# MIMXRT1052 register map
Vendor: nxp.com; File version: 1.0
CPU: CM7 r0p1, little endian, MPU, FPU, VTOR, 4 interrupt priority bits
Registers are 32-bit, read-write, reset 0x0 unless marked. A register's access mark holds for its fields unless they carry their own. Offsets are from the block's base; [hi:lo] are bit positions; {n}, {i} and the like mark numbered series; 'fields as' and 'values as' point back to an identical list.

## IOMUXC (part 3 of 4)
Base 0x401F8000; register names take the prefix IOMUXC_
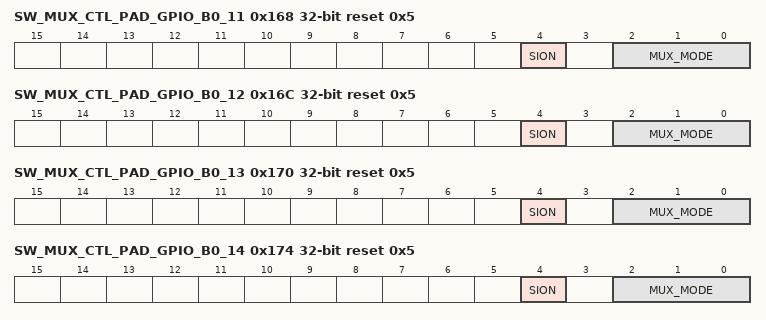
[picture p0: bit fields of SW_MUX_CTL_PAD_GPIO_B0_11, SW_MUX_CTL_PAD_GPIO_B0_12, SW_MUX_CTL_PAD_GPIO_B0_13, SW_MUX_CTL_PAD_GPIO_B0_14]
0x168 SW_MUX_CTL_PAD_GPIO_B0_11 reset 0x5 — SW_MUX_CTL_PAD_GPIO_B0_11 SW MUX Control Register
  [4] SION — Software Input On Field.
    0=DISABLED (Input Path is determined by functionality); 1=ENABLED (Force input path of pad GPIO_B0_11)
  [2:0] MUX_MODE — MUX Mode Select Field. Note: Some functions are available on multiple pins. A given function should not be selected for more than one pin.
    0=ALT0 (Select mux mode: ALT0 mux port: LCD_DATA07 of instance: lcdif); 1=ALT1 (Select mux mode: ALT1 mux port: TMR4_TIMER2 of instance: qtimer4); 2=ALT2 (Select mux mode: ALT2 mux port: FLEXPWM2_PWM2_B of instance: flexpwm2); 3=ALT3 (Select mux mode: ALT3 mux port: SAI1_TX_DATA02 of instance: sai1); 4=ALT4 (Select mux mode: ALT4 mux port: FLEXIO2_D11 of instance: flexio2); 5=ALT5 (Select mux mode: ALT5 mux port: GPIO2_IO11 of instance: gpio2); 6=ALT6 (Select mux mode: ALT6 mux port: SRC_BT_CFG07 of instance: src)
0x16C SW_MUX_CTL_PAD_GPIO_B0_12 reset 0x5 — SW_MUX_CTL_PAD_GPIO_B0_12 SW MUX Control Register
  [4] SION — Software Input On Field.
    0=DISABLED (Input Path is determined by functionality); 1=ENABLED (Force input path of pad GPIO_B0_12)
  [2:0] MUX_MODE — MUX Mode Select Field. Note: Some functions are available on multiple pins. A given function should not be selected for more than one pin.
    0=ALT0 (Select mux mode: ALT0 mux port: LCD_DATA08 of instance: lcdif); 1=ALT1 (Select mux mode: ALT1 mux port: XBAR1_INOUT10 of instance: xbar1); 2=ALT2 (Select mux mode: ALT2 mux port: ARM_TRACE_CLK of instance: cm7_mx6rt); 3=ALT3 (Select mux mode: ALT3 mux port: SAI1_TX_DATA01 of instance: sai1); 4=ALT4 (Select mux mode: ALT4 mux port: FLEXIO2_D12 of instance: flexio2); 5=ALT5 (Select mux mode: ALT5 mux port: GPIO2_IO12 of instance: gpio2); 6=ALT6 (Select mux mode: ALT6 mux port: SRC_BT_CFG08 of instance: src)
0x170 SW_MUX_CTL_PAD_GPIO_B0_13 reset 0x5 — SW_MUX_CTL_PAD_GPIO_B0_13 SW MUX Control Register
  [4] SION — Software Input On Field.
    0=DISABLED (Input Path is determined by functionality); 1=ENABLED (Force input path of pad GPIO_B0_13)
  [2:0] MUX_MODE — MUX Mode Select Field. Note: Some functions are available on multiple pins. A given function should not be selected for more than one pin.
    0=ALT0 (Select mux mode: ALT0 mux port: LCD_DATA09 of instance: lcdif); 1=ALT1 (Select mux mode: ALT1 mux port: XBAR1_INOUT11 of instance: xbar1); 2=ALT2 (Select mux mode: ALT2 mux port: ARM_TRACE_SWO of instance: cm7_mx6rt); 3=ALT3 (Select mux mode: ALT3 mux port: SAI1_MCLK of instance: sai1); 4=ALT4 (Select mux mode: ALT4 mux port: FLEXIO2_D13 of instance: flexio2); 5=ALT5 (Select mux mode: ALT5 mux port: GPIO2_IO13 of instance: gpio2); 6=ALT6 (Select mux mode: ALT6 mux port: SRC_BT_CFG09 of instance: src)
0x174 SW_MUX_CTL_PAD_GPIO_B0_14 reset 0x5 — SW_MUX_CTL_PAD_GPIO_B0_14 SW MUX Control Register
  [4] SION — Software Input On Field.
    0=DISABLED (Input Path is determined by functionality); 1=ENABLED (Force input path of pad GPIO_B0_14)
  [2:0] MUX_MODE — MUX Mode Select Field. Note: Some functions are available on multiple pins. A given function should not be selected for more than one pin.
    0=ALT0 (Select mux mode: ALT0 mux port: LCD_DATA10 of instance: lcdif); 1=ALT1 (Select mux mode: ALT1 mux port: XBAR1_INOUT12 of instance: xbar1); 2=ALT2 (Select mux mode: ALT2 mux port: ARM_CM7_TXEV of instance: cm7_mx6rt); 3=ALT3 (Select mux mode: ALT3 mux port: SAI1_RX_SYNC of instance: sai1); 4=ALT4 (Select mux mode: ALT4 mux port: FLEXIO2_D14 of instance: flexio2); 5=ALT5 (Select mux mode: ALT5 mux port: GPIO2_IO14 of instance: gpio2); 6=ALT6 (Select mux mode: ALT6 mux port: SRC_BT_CFG10 of instance: src)
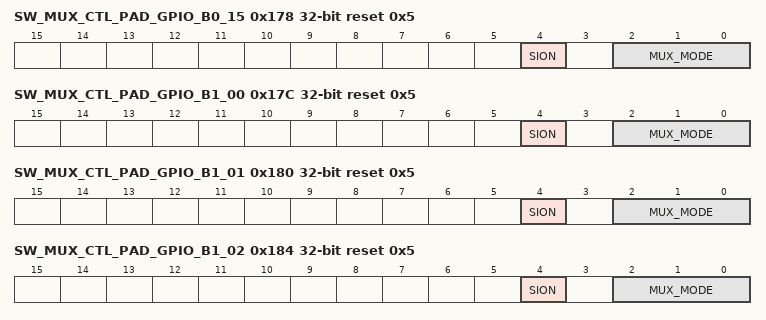
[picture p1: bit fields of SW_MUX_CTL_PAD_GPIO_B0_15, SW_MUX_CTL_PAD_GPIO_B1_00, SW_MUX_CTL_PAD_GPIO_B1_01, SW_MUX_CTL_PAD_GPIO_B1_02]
0x178 SW_MUX_CTL_PAD_GPIO_B0_15 reset 0x5 — SW_MUX_CTL_PAD_GPIO_B0_15 SW MUX Control Register
  [4] SION — Software Input On Field.
    0=DISABLED (Input Path is determined by functionality); 1=ENABLED (Force input path of pad GPIO_B0_15)
  [2:0] MUX_MODE — MUX Mode Select Field. Note: Some functions are available on multiple pins. A given function should not be selected for more than one pin.
    0=ALT0 (Select mux mode: ALT0 mux port: LCD_DATA11 of instance: lcdif); 1=ALT1 (Select mux mode: ALT1 mux port: XBAR1_INOUT13 of instance: xbar1); 2=ALT2 (Select mux mode: ALT2 mux port: ARM_CM7_RXEV of instance: cm7_mx6rt); 3=ALT3 (Select mux mode: ALT3 mux port: SAI1_RX_BCLK of instance: sai1); 4=ALT4 (Select mux mode: ALT4 mux port: FLEXIO2_D15 of instance: flexio2); 5=ALT5 (Select mux mode: ALT5 mux port: GPIO2_IO15 of instance: gpio2); 6=ALT6 (Select mux mode: ALT6 mux port: SRC_BT_CFG11 of instance: src)
0x17C SW_MUX_CTL_PAD_GPIO_B1_00 reset 0x5 — SW_MUX_CTL_PAD_GPIO_B1_00 SW MUX Control Register
  [4] SION — Software Input On Field.
    0=DISABLED (Input Path is determined by functionality); 1=ENABLED (Force input path of pad GPIO_B1_00)
  [2:0] MUX_MODE — MUX Mode Select Field. Note: Some functions are available on multiple pins. A given function should not be selected for more than one pin.
    0=ALT0 (Select mux mode: ALT0 mux port: LCD_DATA12 of instance: lcdif); 1=ALT1 (Select mux mode: ALT1 mux port: XBAR1_INOUT14 of instance: xbar1); 2=ALT2 (Select mux mode: ALT2 mux port: LPUART4_TXD of instance: lpuart4); 3=ALT3 (Select mux mode: ALT3 mux port: SAI1_RX_DATA00 of instance: sai1); 4=ALT4 (Select mux mode: ALT4 mux port: FLEXIO2_D16 of instance: flexio2); 5=ALT5 (Select mux mode: ALT5 mux port: GPIO2_IO16 of instance: gpio2); 6=ALT6 (Select mux mode: ALT6 mux port: FLEXPWM1_PWM3_A of instance: flexpwm1)
0x180 SW_MUX_CTL_PAD_GPIO_B1_01 reset 0x5 — SW_MUX_CTL_PAD_GPIO_B1_01 SW MUX Control Register
  [4] SION — Software Input On Field.
    0=DISABLED (Input Path is determined by functionality); 1=ENABLED (Force input path of pad GPIO_B1_01)
  [2:0] MUX_MODE — MUX Mode Select Field. Note: Some functions are available on multiple pins. A given function should not be selected for more than one pin.
    0=ALT0 (Select mux mode: ALT0 mux port: LCD_DATA13 of instance: lcdif); 1=ALT1 (Select mux mode: ALT1 mux port: XBAR1_INOUT15 of instance: xbar1); 2=ALT2 (Select mux mode: ALT2 mux port: LPUART4_RXD of instance: lpuart4); 3=ALT3 (Select mux mode: ALT3 mux port: SAI1_TX_DATA00 of instance: sai1); 4=ALT4 (Select mux mode: ALT4 mux port: FLEXIO2_D17 of instance: flexio2); 5=ALT5 (Select mux mode: ALT5 mux port: GPIO2_IO17 of instance: gpio2); 6=ALT6 (Select mux mode: ALT6 mux port: FLEXPWM1_PWM3_B of instance: flexpwm1)
0x184 SW_MUX_CTL_PAD_GPIO_B1_02 reset 0x5 — SW_MUX_CTL_PAD_GPIO_B1_02 SW MUX Control Register
  [4] SION — Software Input On Field.
    0=DISABLED (Input Path is determined by functionality); 1=ENABLED (Force input path of pad GPIO_B1_02)
  [2:0] MUX_MODE — MUX Mode Select Field. Note: Some functions are available on multiple pins. A given function should not be selected for more than one pin.
    0=ALT0 (Select mux mode: ALT0 mux port: LCD_DATA14 of instance: lcdif); 1=ALT1 (Select mux mode: ALT1 mux port: XBAR1_INOUT16 of instance: xbar1); 2=ALT2 (Select mux mode: ALT2 mux port: LPSPI4_PCS2 of instance: lpspi4); 3=ALT3 (Select mux mode: ALT3 mux port: SAI1_TX_BCLK of instance: sai1); 4=ALT4 (Select mux mode: ALT4 mux port: FLEXIO2_D18 of instance: flexio2); 5=ALT5 (Select mux mode: ALT5 mux port: GPIO2_IO18 of instance: gpio2); 6=ALT6 (Select mux mode: ALT6 mux port: FLEXPWM2_PWM3_A of instance: flexpwm2)
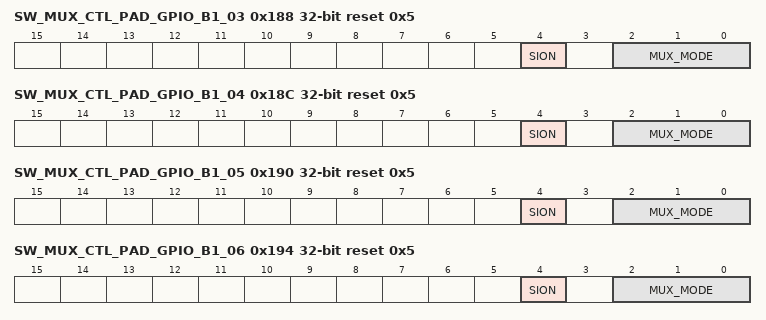
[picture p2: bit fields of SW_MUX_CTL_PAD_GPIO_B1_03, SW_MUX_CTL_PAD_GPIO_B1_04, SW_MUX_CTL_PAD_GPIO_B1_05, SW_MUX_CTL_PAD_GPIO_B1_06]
0x188 SW_MUX_CTL_PAD_GPIO_B1_03 reset 0x5 — SW_MUX_CTL_PAD_GPIO_B1_03 SW MUX Control Register
  [4] SION — Software Input On Field.
    0=DISABLED (Input Path is determined by functionality); 1=ENABLED (Force input path of pad GPIO_B1_03)
  [2:0] MUX_MODE — MUX Mode Select Field. Note: Some functions are available on multiple pins. A given function should not be selected for more than one pin.
    0=ALT0 (Select mux mode: ALT0 mux port: LCD_DATA15 of instance: lcdif); 1=ALT1 (Select mux mode: ALT1 mux port: XBAR1_INOUT17 of instance: xbar1); 2=ALT2 (Select mux mode: ALT2 mux port: LPSPI4_PCS1 of instance: lpspi4); 3=ALT3 (Select mux mode: ALT3 mux port: SAI1_TX_SYNC of instance: sai1); 4=ALT4 (Select mux mode: ALT4 mux port: FLEXIO2_D19 of instance: flexio2); 5=ALT5 (Select mux mode: ALT5 mux port: GPIO2_IO19 of instance: gpio2); 6=ALT6 (Select mux mode: ALT6 mux port: FLEXPWM2_PWM3_B of instance: flexpwm2)
0x18C SW_MUX_CTL_PAD_GPIO_B1_04 reset 0x5 — SW_MUX_CTL_PAD_GPIO_B1_04 SW MUX Control Register
  [4] SION — Software Input On Field.
    0=DISABLED (Input Path is determined by functionality); 1=ENABLED (Force input path of pad GPIO_B1_04)
  [2:0] MUX_MODE — MUX Mode Select Field. Note: Some functions are available on multiple pins. A given function should not be selected for more than one pin.
    0=ALT0 (Select mux mode: ALT0 mux port: LCD_DATA16 of instance: lcdif); 1=ALT1 (Select mux mode: ALT1 mux port: LPSPI4_PCS0 of instance: lpspi4); 2=ALT2 (Select mux mode: ALT2 mux port: CSI_DATA15 of instance: csi); 3=ALT3 (Select mux mode: ALT3 mux port: ENET_RX_DATA00 of instance: enet); 4=ALT4 (Select mux mode: ALT4 mux port: FLEXIO2_D20 of instance: flexio2); 5=ALT5 (Select mux mode: ALT5 mux port: GPIO2_IO20 of instance: gpio2)
0x190 SW_MUX_CTL_PAD_GPIO_B1_05 reset 0x5 — SW_MUX_CTL_PAD_GPIO_B1_05 SW MUX Control Register
  [4] SION — Software Input On Field.
    0=DISABLED (Input Path is determined by functionality); 1=ENABLED (Force input path of pad GPIO_B1_05)
  [2:0] MUX_MODE — MUX Mode Select Field. Note: Some functions are available on multiple pins. A given function should not be selected for more than one pin.
    0=ALT0 (Select mux mode: ALT0 mux port: LCD_DATA17 of instance: lcdif); 1=ALT1 (Select mux mode: ALT1 mux port: LPSPI4_SDI of instance: lpspi4); 2=ALT2 (Select mux mode: ALT2 mux port: CSI_DATA14 of instance: csi); 3=ALT3 (Select mux mode: ALT3 mux port: ENET_RX_DATA01 of instance: enet); 4=ALT4 (Select mux mode: ALT4 mux port: FLEXIO2_D21 of instance: flexio2); 5=ALT5 (Select mux mode: ALT5 mux port: GPIO2_IO21 of instance: gpio2)
0x194 SW_MUX_CTL_PAD_GPIO_B1_06 reset 0x5 — SW_MUX_CTL_PAD_GPIO_B1_06 SW MUX Control Register
  [4] SION — Software Input On Field.
    0=DISABLED (Input Path is determined by functionality); 1=ENABLED (Force input path of pad GPIO_B1_06)
  [2:0] MUX_MODE — MUX Mode Select Field. Note: Some functions are available on multiple pins. A given function should not be selected for more than one pin.
    0=ALT0 (Select mux mode: ALT0 mux port: LCD_DATA18 of instance: lcdif); 1=ALT1 (Select mux mode: ALT1 mux port: LPSPI4_SDO of instance: lpspi4); 2=ALT2 (Select mux mode: ALT2 mux port: CSI_DATA13 of instance: csi); 3=ALT3 (Select mux mode: ALT3 mux port: ENET_RX_EN of instance: enet); 4=ALT4 (Select mux mode: ALT4 mux port: FLEXIO2_D22 of instance: flexio2); 5=ALT5 (Select mux mode: ALT5 mux port: GPIO2_IO22 of instance: gpio2)
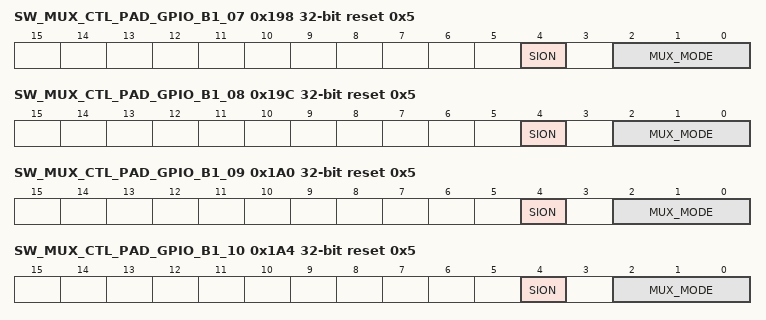
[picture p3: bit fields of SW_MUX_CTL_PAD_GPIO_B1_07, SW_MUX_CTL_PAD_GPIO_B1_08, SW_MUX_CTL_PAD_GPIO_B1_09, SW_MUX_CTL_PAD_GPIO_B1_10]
0x198 SW_MUX_CTL_PAD_GPIO_B1_07 reset 0x5 — SW_MUX_CTL_PAD_GPIO_B1_07 SW MUX Control Register
  [4] SION — Software Input On Field.
    0=DISABLED (Input Path is determined by functionality); 1=ENABLED (Force input path of pad GPIO_B1_07)
  [2:0] MUX_MODE — MUX Mode Select Field. Note: Some functions are available on multiple pins. A given function should not be selected for more than one pin.
    0=ALT0 (Select mux mode: ALT0 mux port: LCD_DATA19 of instance: lcdif); 1=ALT1 (Select mux mode: ALT1 mux port: LPSPI4_SCK of instance: lpspi4); 2=ALT2 (Select mux mode: ALT2 mux port: CSI_DATA12 of instance: csi); 3=ALT3 (Select mux mode: ALT3 mux port: ENET_TX_DATA00 of instance: enet); 4=ALT4 (Select mux mode: ALT4 mux port: FLEXIO2_D23 of instance: flexio2); 5=ALT5 (Select mux mode: ALT5 mux port: GPIO2_IO23 of instance: gpio2)
0x19C SW_MUX_CTL_PAD_GPIO_B1_08 reset 0x5 — SW_MUX_CTL_PAD_GPIO_B1_08 SW MUX Control Register
  [4] SION — Software Input On Field.
    0=DISABLED (Input Path is determined by functionality); 1=ENABLED (Force input path of pad GPIO_B1_08)
  [2:0] MUX_MODE — MUX Mode Select Field. Note: Some functions are available on multiple pins. A given function should not be selected for more than one pin.
    0=ALT0 (Select mux mode: ALT0 mux port: LCD_DATA20 of instance: lcdif); 1=ALT1 (Select mux mode: ALT1 mux port: TMR1_TIMER3 of instance: qtimer1); 2=ALT2 (Select mux mode: ALT2 mux port: CSI_DATA11 of instance: csi); 3=ALT3 (Select mux mode: ALT3 mux port: ENET_TX_DATA01 of instance: enet); 4=ALT4 (Select mux mode: ALT4 mux port: FLEXIO2_D24 of instance: flexio2); 5=ALT5 (Select mux mode: ALT5 mux port: GPIO2_IO24 of instance: gpio2); 6=ALT6 (Select mux mode: ALT6 mux port: FLEXCAN2_TX of instance: flexcan2)
0x1A0 SW_MUX_CTL_PAD_GPIO_B1_09 reset 0x5 — SW_MUX_CTL_PAD_GPIO_B1_09 SW MUX Control Register
  [4] SION — Software Input On Field.
    0=DISABLED (Input Path is determined by functionality); 1=ENABLED (Force input path of pad GPIO_B1_09)
  [2:0] MUX_MODE — MUX Mode Select Field. Note: Some functions are available on multiple pins. A given function should not be selected for more than one pin.
    0=ALT0 (Select mux mode: ALT0 mux port: LCD_DATA21 of instance: lcdif); 1=ALT1 (Select mux mode: ALT1 mux port: TMR2_TIMER3 of instance: qtimer2); 2=ALT2 (Select mux mode: ALT2 mux port: CSI_DATA10 of instance: csi); 3=ALT3 (Select mux mode: ALT3 mux port: ENET_TX_EN of instance: enet); 4=ALT4 (Select mux mode: ALT4 mux port: FLEXIO2_D25 of instance: flexio2); 5=ALT5 (Select mux mode: ALT5 mux port: GPIO2_IO25 of instance: gpio2); 6=ALT6 (Select mux mode: ALT6 mux port: FLEXCAN2_RX of instance: flexcan2)
0x1A4 SW_MUX_CTL_PAD_GPIO_B1_10 reset 0x5 — SW_MUX_CTL_PAD_GPIO_B1_10 SW MUX Control Register
  [4] SION — Software Input On Field.
    0=DISABLED (Input Path is determined by functionality); 1=ENABLED (Force input path of pad GPIO_B1_10)
  [2:0] MUX_MODE — MUX Mode Select Field. Note: Some functions are available on multiple pins. A given function should not be selected for more than one pin.
    0=ALT0 (Select mux mode: ALT0 mux port: LCD_DATA22 of instance: lcdif); 1=ALT1 (Select mux mode: ALT1 mux port: TMR3_TIMER3 of instance: qtimer3); 2=ALT2 (Select mux mode: ALT2 mux port: CSI_DATA00 of instance: csi); 3=ALT3 (Select mux mode: ALT3 mux port: ENET_TX_CLK of instance: enet); 4=ALT4 (Select mux mode: ALT4 mux port: FLEXIO2_D26 of instance: flexio2); 5=ALT5 (Select mux mode: ALT5 mux port: GPIO2_IO26 of instance: gpio2); 6=ALT6 (Select mux mode: ALT6 mux port: ENET_REF_CLK of instance: enet)
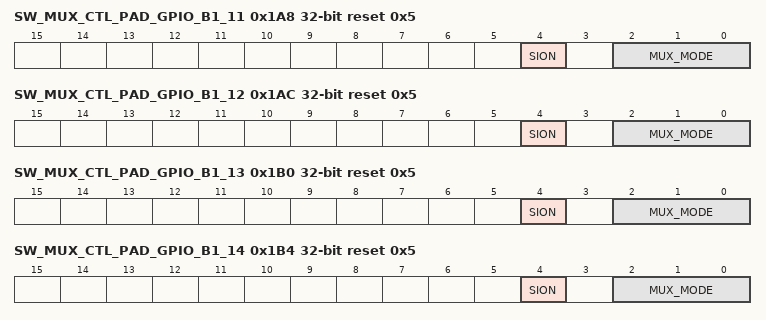
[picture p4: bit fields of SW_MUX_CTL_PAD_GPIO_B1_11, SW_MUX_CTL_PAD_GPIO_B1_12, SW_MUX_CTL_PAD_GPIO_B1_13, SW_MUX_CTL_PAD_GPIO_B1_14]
0x1A8 SW_MUX_CTL_PAD_GPIO_B1_11 reset 0x5 — SW_MUX_CTL_PAD_GPIO_B1_11 SW MUX Control Register
  [4] SION — Software Input On Field.
    0=DISABLED (Input Path is determined by functionality); 1=ENABLED (Force input path of pad GPIO_B1_11)
  [2:0] MUX_MODE — MUX Mode Select Field. Note: Some functions are available on multiple pins. A given function should not be selected for more than one pin.
    0=ALT0 (Select mux mode: ALT0 mux port: LCD_DATA23 of instance: lcdif); 1=ALT1 (Select mux mode: ALT1 mux port: TMR4_TIMER3 of instance: qtimer4); 2=ALT2 (Select mux mode: ALT2 mux port: CSI_DATA01 of instance: csi); 3=ALT3 (Select mux mode: ALT3 mux port: ENET_RX_ER of instance: enet); 4=ALT4 (Select mux mode: ALT4 mux port: FLEXIO2_D27 of instance: flexio2); 5=ALT5 (Select mux mode: ALT5 mux port: GPIO2_IO27 of instance: gpio2); 6=ALT6 (Select mux mode: ALT6 mux port: LPSPI4_PCS3 of instance: lpspi4)
0x1AC SW_MUX_CTL_PAD_GPIO_B1_12 reset 0x5 — SW_MUX_CTL_PAD_GPIO_B1_12 SW MUX Control Register
  [4] SION — Software Input On Field.
    0=DISABLED (Input Path is determined by functionality); 1=ENABLED (Force input path of pad GPIO_B1_12)
  [2:0] MUX_MODE — MUX Mode Select Field. Note: Some functions are available on multiple pins. A given function should not be selected for more than one pin.
    1=ALT1 (Select mux mode: ALT1 mux port: LPUART5_TXD of instance: lpuart5); 2=ALT2 (Select mux mode: ALT2 mux port: CSI_PIXCLK of instance: csi); 3=ALT3 (Select mux mode: ALT3 mux port: ENET_1588_EVENT0_IN of instance: enet); 4=ALT4 (Select mux mode: ALT4 mux port: FLEXIO2_D28 of instance: flexio2); 5=ALT5 (Select mux mode: ALT5 mux port: GPIO2_IO28 of instance: gpio2); 6=ALT6 (Select mux mode: ALT6 mux port: USDHC1_CD_B of instance: usdhc1)
0x1B0 SW_MUX_CTL_PAD_GPIO_B1_13 reset 0x5 — SW_MUX_CTL_PAD_GPIO_B1_13 SW MUX Control Register
  [4] SION — Software Input On Field.
    0=DISABLED (Input Path is determined by functionality); 1=ENABLED (Force input path of pad GPIO_B1_13)
  [2:0] MUX_MODE — MUX Mode Select Field. Note: Some functions are available on multiple pins. A given function should not be selected for more than one pin.
    0=ALT0 (Select mux mode: ALT0 mux port: WDOG1_B of instance: wdog1); 1=ALT1 (Select mux mode: ALT1 mux port: LPUART5_RXD of instance: lpuart5); 2=ALT2 (Select mux mode: ALT2 mux port: CSI_VSYNC of instance: csi); 3=ALT3 (Select mux mode: ALT3 mux port: ENET_1588_EVENT0_OUT of instance: enet); 4=ALT4 (Select mux mode: ALT4 mux port: FLEXIO2_D29 of instance: flexio2); 5=ALT5 (Select mux mode: ALT5 mux port: GPIO2_IO29 of instance: gpio2); 6=ALT6 (Select mux mode: ALT6 mux port: USDHC1_WP of instance: usdhc1)
0x1B4 SW_MUX_CTL_PAD_GPIO_B1_14 reset 0x5 — SW_MUX_CTL_PAD_GPIO_B1_14 SW MUX Control Register
  [4] SION — Software Input On Field.
    0=DISABLED (Input Path is determined by functionality); 1=ENABLED (Force input path of pad GPIO_B1_14)
  [2:0] MUX_MODE — MUX Mode Select Field. Note: Some functions are available on multiple pins. A given function should not be selected for more than one pin.
    0=ALT0 (Select mux mode: ALT0 mux port: ENET_MDC of instance: enet); 1=ALT1 (Select mux mode: ALT1 mux port: FLEXPWM4_PWM2_A of instance: flexpwm4); 2=ALT2 (Select mux mode: ALT2 mux port: CSI_HSYNC of instance: csi); 3=ALT3 (Select mux mode: ALT3 mux port: XBAR1_IN02 of instance: xbar1); 4=ALT4 (Select mux mode: ALT4 mux port: FLEXIO2_D30 of instance: flexio2); 5=ALT5 (Select mux mode: ALT5 mux port: GPIO2_IO30 of instance: gpio2); 6=ALT6 (Select mux mode: ALT6 mux port: USDHC1_VSELECT of instance: usdhc1)
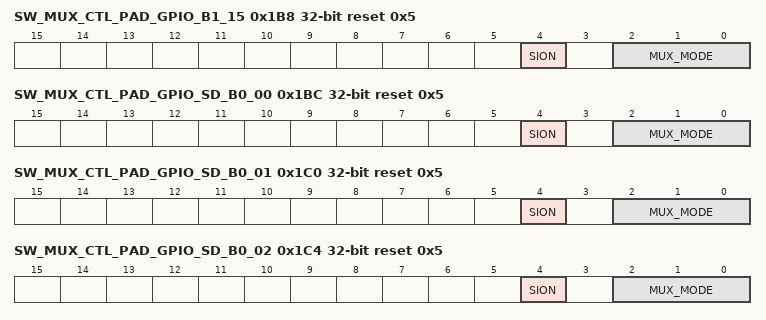
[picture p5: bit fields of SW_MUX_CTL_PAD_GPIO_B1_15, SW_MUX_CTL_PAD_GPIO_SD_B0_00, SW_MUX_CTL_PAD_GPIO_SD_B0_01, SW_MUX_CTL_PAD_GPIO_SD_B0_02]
0x1B8 SW_MUX_CTL_PAD_GPIO_B1_15 reset 0x5 — SW_MUX_CTL_PAD_GPIO_B1_15 SW MUX Control Register
  [4] SION — Software Input On Field.
    0=DISABLED (Input Path is determined by functionality); 1=ENABLED (Force input path of pad GPIO_B1_15)
  [2:0] MUX_MODE — MUX Mode Select Field. Note: Some functions are available on multiple pins. A given function should not be selected for more than one pin.
    0=ALT0 (Select mux mode: ALT0 mux port: ENET_MDIO of instance: enet); 1=ALT1 (Select mux mode: ALT1 mux port: FLEXPWM4_PWM3_A of instance: flexpwm4); 2=ALT2 (Select mux mode: ALT2 mux port: CSI_MCLK of instance: csi); 3=ALT3 (Select mux mode: ALT3 mux port: XBAR1_IN03 of instance: xbar1); 4=ALT4 (Select mux mode: ALT4 mux port: FLEXIO2_D31 of instance: flexio2); 5=ALT5 (Select mux mode: ALT5 mux port: GPIO2_IO31 of instance: gpio2); 6=ALT6 (Select mux mode: ALT6 mux port: USDHC1_RESET_B of instance: usdhc1)
0x1BC SW_MUX_CTL_PAD_GPIO_SD_B0_00 reset 0x5 — SW_MUX_CTL_PAD_GPIO_SD_B0_00 SW MUX Control Register
  [4] SION — Software Input On Field.
    0=DISABLED (Input Path is determined by functionality); 1=ENABLED (Force input path of pad GPIO_SD_B0_00)
  [2:0] MUX_MODE — MUX Mode Select Field. Note: Some functions are available on multiple pins. A given function should not be selected for more than one pin.
    0=ALT0 (Select mux mode: ALT0 mux port: USDHC1_CMD of instance: usdhc1); 1=ALT1 (Select mux mode: ALT1 mux port: FLEXPWM1_PWM0_A of instance: flexpwm1); 2=ALT2 (Select mux mode: ALT2 mux port: LPI2C3_SCL of instance: lpi2c3); 3=ALT3 (Select mux mode: ALT3 mux port: XBAR1_INOUT04 of instance: xbar1); 4=ALT4 (Select mux mode: ALT4 mux port: LPSPI1_SCK of instance: lpspi1); 5=ALT5 (Select mux mode: ALT5 mux port: GPIO3_IO12 of instance: gpio3); 6=ALT6 (Select mux mode: ALT6 mux port: FLEXSPI_A_SS1_B of instance: flexspi)
0x1C0 SW_MUX_CTL_PAD_GPIO_SD_B0_01 reset 0x5 — SW_MUX_CTL_PAD_GPIO_SD_B0_01 SW MUX Control Register
  [4] SION — Software Input On Field.
    0=DISABLED (Input Path is determined by functionality); 1=ENABLED (Force input path of pad GPIO_SD_B0_01)
  [2:0] MUX_MODE — MUX Mode Select Field. Note: Some functions are available on multiple pins. A given function should not be selected for more than one pin.
    0=ALT0 (Select mux mode: ALT0 mux port: USDHC1_CLK of instance: usdhc1); 1=ALT1 (Select mux mode: ALT1 mux port: FLEXPWM1_PWM0_B of instance: flexpwm1); 2=ALT2 (Select mux mode: ALT2 mux port: LPI2C3_SDA of instance: lpi2c3); 3=ALT3 (Select mux mode: ALT3 mux port: XBAR1_INOUT05 of instance: xbar1); 4=ALT4 (Select mux mode: ALT4 mux port: LPSPI1_PCS0 of instance: lpspi1); 5=ALT5 (Select mux mode: ALT5 mux port: GPIO3_IO13 of instance: gpio3); 6=ALT6 (Select mux mode: ALT6 mux port: FLEXSPI_B_SS1_B of instance: flexspi)
0x1C4 SW_MUX_CTL_PAD_GPIO_SD_B0_02 reset 0x5 — SW_MUX_CTL_PAD_GPIO_SD_B0_02 SW MUX Control Register
  [4] SION — Software Input On Field.
    0=DISABLED (Input Path is determined by functionality); 1=ENABLED (Force input path of pad GPIO_SD_B0_02)
  [2:0] MUX_MODE — MUX Mode Select Field. Note: Some functions are available on multiple pins. A given function should not be selected for more than one pin.
    0=ALT0 (Select mux mode: ALT0 mux port: USDHC1_DATA0 of instance: usdhc1); 1=ALT1 (Select mux mode: ALT1 mux port: FLEXPWM1_PWM1_A of instance: flexpwm1); 2=ALT2 (Select mux mode: ALT2 mux port: LPUART8_CTS_B of instance: lpuart8); 3=ALT3 (Select mux mode: ALT3 mux port: XBAR1_INOUT06 of instance: xbar1); 4=ALT4 (Select mux mode: ALT4 mux port: LPSPI1_SDO of instance: lpspi1); 5=ALT5 (Select mux mode: ALT5 mux port: GPIO3_IO14 of instance: gpio3)
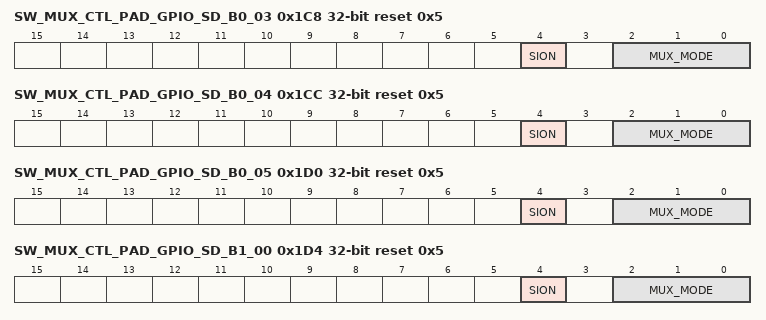
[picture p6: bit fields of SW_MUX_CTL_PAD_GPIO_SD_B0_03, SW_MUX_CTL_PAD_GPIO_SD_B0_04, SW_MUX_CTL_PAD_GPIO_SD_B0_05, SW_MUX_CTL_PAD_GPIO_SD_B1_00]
0x1C8 SW_MUX_CTL_PAD_GPIO_SD_B0_03 reset 0x5 — SW_MUX_CTL_PAD_GPIO_SD_B0_03 SW MUX Control Register
  [4] SION — Software Input On Field.
    0=DISABLED (Input Path is determined by functionality); 1=ENABLED (Force input path of pad GPIO_SD_B0_03)
  [2:0] MUX_MODE — MUX Mode Select Field. Note: Some functions are available on multiple pins. A given function should not be selected for more than one pin.
    0=ALT0 (Select mux mode: ALT0 mux port: USDHC1_DATA1 of instance: usdhc1); 1=ALT1 (Select mux mode: ALT1 mux port: FLEXPWM1_PWM1_B of instance: flexpwm1); 2=ALT2 (Select mux mode: ALT2 mux port: LPUART8_RTS_B of instance: lpuart8); 3=ALT3 (Select mux mode: ALT3 mux port: XBAR1_INOUT07 of instance: xbar1); 4=ALT4 (Select mux mode: ALT4 mux port: LPSPI1_SDI of instance: lpspi1); 5=ALT5 (Select mux mode: ALT5 mux port: GPIO3_IO15 of instance: gpio3)
0x1CC SW_MUX_CTL_PAD_GPIO_SD_B0_04 reset 0x5 — SW_MUX_CTL_PAD_GPIO_SD_B0_04 SW MUX Control Register
  [4] SION — Software Input On Field.
    0=DISABLED (Input Path is determined by functionality); 1=ENABLED (Force input path of pad GPIO_SD_B0_04)
  [2:0] MUX_MODE — MUX Mode Select Field. Note: Some functions are available on multiple pins. A given function should not be selected for more than one pin.
    0=ALT0 (Select mux mode: ALT0 mux port: USDHC1_DATA2 of instance: usdhc1); 1=ALT1 (Select mux mode: ALT1 mux port: FLEXPWM1_PWM2_A of instance: flexpwm1); 2=ALT2 (Select mux mode: ALT2 mux port: LPUART8_TXD of instance: lpuart8); 3=ALT3 (Select mux mode: ALT3 mux port: XBAR1_INOUT08 of instance: xbar1); 4=ALT4 (Select mux mode: ALT4 mux port: FLEXSPI_B_SS0_B of instance: flexspi); 5=ALT5 (Select mux mode: ALT5 mux port: GPIO3_IO16 of instance: gpio3); 6=ALT6 (Select mux mode: ALT6 mux port: CCM_CLKO1 of instance: ccm)
0x1D0 SW_MUX_CTL_PAD_GPIO_SD_B0_05 reset 0x5 — SW_MUX_CTL_PAD_GPIO_SD_B0_05 SW MUX Control Register
  [4] SION — Software Input On Field.
    0=DISABLED (Input Path is determined by functionality); 1=ENABLED (Force input path of pad GPIO_SD_B0_05)
  [2:0] MUX_MODE — MUX Mode Select Field. Note: Some functions are available on multiple pins. A given function should not be selected for more than one pin.
    0=ALT0 (Select mux mode: ALT0 mux port: USDHC1_DATA3 of instance: usdhc1); 1=ALT1 (Select mux mode: ALT1 mux port: FLEXPWM1_PWM2_B of instance: flexpwm1); 2=ALT2 (Select mux mode: ALT2 mux port: LPUART8_RXD of instance: lpuart8); 3=ALT3 (Select mux mode: ALT3 mux port: XBAR1_INOUT09 of instance: xbar1); 4=ALT4 (Select mux mode: ALT4 mux port: FLEXSPI_B_DQS of instance: flexspi); 5=ALT5 (Select mux mode: ALT5 mux port: GPIO3_IO17 of instance: gpio3); 6=ALT6 (Select mux mode: ALT6 mux port: CCM_CLKO2 of instance: ccm)
0x1D4 SW_MUX_CTL_PAD_GPIO_SD_B1_00 reset 0x5 — SW_MUX_CTL_PAD_GPIO_SD_B1_00 SW MUX Control Register
  [4] SION — Software Input On Field.
    0=DISABLED (Input Path is determined by functionality); 1=ENABLED (Force input path of pad GPIO_SD_B1_00)
  [2:0] MUX_MODE — MUX Mode Select Field. Note: Some functions are available on multiple pins. A given function should not be selected for more than one pin.
    0=ALT0 (Select mux mode: ALT0 mux port: USDHC2_DATA3 of instance: usdhc2); 1=ALT1 (Select mux mode: ALT1 mux port: FLEXSPI_B_DATA3 of instance: flexspi); 2=ALT2 (Select mux mode: ALT2 mux port: FLEXPWM1_PWM3_A of instance: flexpwm1); 3=ALT3 (Select mux mode: ALT3 mux port: SAI1_TX_DATA03 of instance: sai1); 4=ALT4 (Select mux mode: ALT4 mux port: LPUART4_TXD of instance: lpuart4); 5=ALT5 (Select mux mode: ALT5 mux port: GPIO3_IO00 of instance: gpio3)
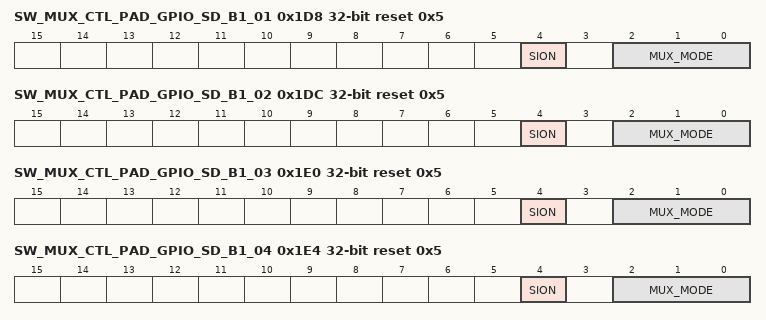
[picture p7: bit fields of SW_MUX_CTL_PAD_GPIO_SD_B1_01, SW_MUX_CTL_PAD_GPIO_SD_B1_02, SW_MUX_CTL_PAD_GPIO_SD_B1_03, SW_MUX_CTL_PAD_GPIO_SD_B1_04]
0x1D8 SW_MUX_CTL_PAD_GPIO_SD_B1_01 reset 0x5 — SW_MUX_CTL_PAD_GPIO_SD_B1_01 SW MUX Control Register
  [4] SION — Software Input On Field.
    0=DISABLED (Input Path is determined by functionality); 1=ENABLED (Force input path of pad GPIO_SD_B1_01)
  [2:0] MUX_MODE — MUX Mode Select Field. Note: Some functions are available on multiple pins. A given function should not be selected for more than one pin.
    0=ALT0 (Select mux mode: ALT0 mux port: USDHC2_DATA2 of instance: usdhc2); 1=ALT1 (Select mux mode: ALT1 mux port: FLEXSPI_B_DATA2 of instance: flexspi); 2=ALT2 (Select mux mode: ALT2 mux port: FLEXPWM1_PWM3_B of instance: flexpwm1); 3=ALT3 (Select mux mode: ALT3 mux port: SAI1_TX_DATA02 of instance: sai1); 4=ALT4 (Select mux mode: ALT4 mux port: LPUART4_RXD of instance: lpuart4); 5=ALT5 (Select mux mode: ALT5 mux port: GPIO3_IO01 of instance: gpio3)
0x1DC SW_MUX_CTL_PAD_GPIO_SD_B1_02 reset 0x5 — SW_MUX_CTL_PAD_GPIO_SD_B1_02 SW MUX Control Register
  [4] SION — Software Input On Field.
    0=DISABLED (Input Path is determined by functionality); 1=ENABLED (Force input path of pad GPIO_SD_B1_02)
  [2:0] MUX_MODE — MUX Mode Select Field. Note: Some functions are available on multiple pins. A given function should not be selected for more than one pin.
    0=ALT0 (Select mux mode: ALT0 mux port: USDHC2_DATA1 of instance: usdhc2); 1=ALT1 (Select mux mode: ALT1 mux port: FLEXSPI_B_DATA1 of instance: flexspi); 2=ALT2 (Select mux mode: ALT2 mux port: FLEXPWM2_PWM3_A of instance: flexpwm2); 3=ALT3 (Select mux mode: ALT3 mux port: SAI1_TX_DATA01 of instance: sai1); 4=ALT4 (Select mux mode: ALT4 mux port: FLEXCAN1_TX of instance: flexcan1); 5=ALT5 (Select mux mode: ALT5 mux port: GPIO3_IO02 of instance: gpio3); 6=ALT6 (Select mux mode: ALT6 mux port: CCM_WAIT of instance: ccm)
0x1E0 SW_MUX_CTL_PAD_GPIO_SD_B1_03 reset 0x5 — SW_MUX_CTL_PAD_GPIO_SD_B1_03 SW MUX Control Register
  [4] SION — Software Input On Field.
    0=DISABLED (Input Path is determined by functionality); 1=ENABLED (Force input path of pad GPIO_SD_B1_03)
  [2:0] MUX_MODE — MUX Mode Select Field. Note: Some functions are available on multiple pins. A given function should not be selected for more than one pin.
    0=ALT0 (Select mux mode: ALT0 mux port: USDHC2_DATA0 of instance: usdhc2); 1=ALT1 (Select mux mode: ALT1 mux port: FLEXSPI_B_DATA0 of instance: flexspi); 2=ALT2 (Select mux mode: ALT2 mux port: FLEXPWM2_PWM3_B of instance: flexpwm2); 3=ALT3 (Select mux mode: ALT3 mux port: SAI1_MCLK of instance: sai1); 4=ALT4 (Select mux mode: ALT4 mux port: FLEXCAN1_RX of instance: flexcan1); 5=ALT5 (Select mux mode: ALT5 mux port: GPIO3_IO03 of instance: gpio3); 6=ALT6 (Select mux mode: ALT6 mux port: CCM_PMIC_READY of instance: ccm)
0x1E4 SW_MUX_CTL_PAD_GPIO_SD_B1_04 reset 0x5 — SW_MUX_CTL_PAD_GPIO_SD_B1_04 SW MUX Control Register
  [4] SION — Software Input On Field.
    0=DISABLED (Input Path is determined by functionality); 1=ENABLED (Force input path of pad GPIO_SD_B1_04)
  [2:0] MUX_MODE — MUX Mode Select Field. Note: Some functions are available on multiple pins. A given function should not be selected for more than one pin.
    0=ALT0 (Select mux mode: ALT0 mux port: USDHC2_CLK of instance: usdhc2); 1=ALT1 (Select mux mode: ALT1 mux port: FLEXSPI_B_SCLK of instance: flexspi); 2=ALT2 (Select mux mode: ALT2 mux port: LPI2C1_SCL of instance: lpi2c1); 3=ALT3 (Select mux mode: ALT3 mux port: SAI1_RX_SYNC of instance: sai1); 4=ALT4 (Select mux mode: ALT4 mux port: FLEXSPI_A_SS1_B of instance: flexspi); 5=ALT5 (Select mux mode: ALT5 mux port: GPIO3_IO04 of instance: gpio3); 6=ALT6 (Select mux mode: ALT6 mux port: CCM_STOP of instance: ccm)
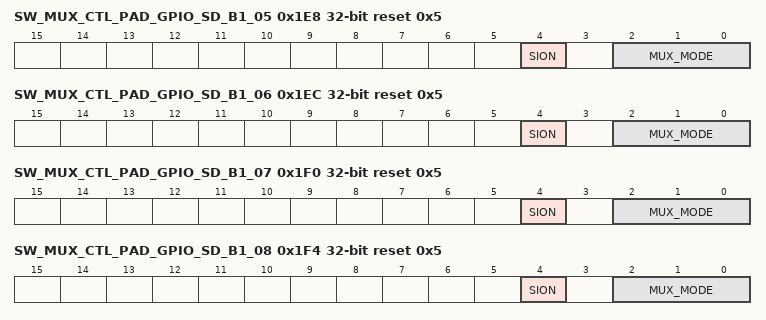
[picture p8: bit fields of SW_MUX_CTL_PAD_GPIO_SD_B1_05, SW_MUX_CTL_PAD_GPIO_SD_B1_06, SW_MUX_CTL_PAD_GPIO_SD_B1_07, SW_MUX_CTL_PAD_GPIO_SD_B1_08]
0x1E8 SW_MUX_CTL_PAD_GPIO_SD_B1_05 reset 0x5 — SW_MUX_CTL_PAD_GPIO_SD_B1_05 SW MUX Control Register
  [4] SION — Software Input On Field.
    0=DISABLED (Input Path is determined by functionality); 1=ENABLED (Force input path of pad GPIO_SD_B1_05)
  [2:0] MUX_MODE — MUX Mode Select Field. Note: Some functions are available on multiple pins. A given function should not be selected for more than one pin.
    0=ALT0 (Select mux mode: ALT0 mux port: USDHC2_CMD of instance: usdhc2); 1=ALT1 (Select mux mode: ALT1 mux port: FLEXSPI_A_DQS of instance: flexspi); 2=ALT2 (Select mux mode: ALT2 mux port: LPI2C1_SDA of instance: lpi2c1); 3=ALT3 (Select mux mode: ALT3 mux port: SAI1_RX_BCLK of instance: sai1); 4=ALT4 (Select mux mode: ALT4 mux port: FLEXSPI_B_SS0_B of instance: flexspi); 5=ALT5 (Select mux mode: ALT5 mux port: GPIO3_IO05 of instance: gpio3)
0x1EC SW_MUX_CTL_PAD_GPIO_SD_B1_06 reset 0x5 — SW_MUX_CTL_PAD_GPIO_SD_B1_06 SW MUX Control Register
  [4] SION — Software Input On Field.
    0=DISABLED (Input Path is determined by functionality); 1=ENABLED (Force input path of pad GPIO_SD_B1_06)
  [2:0] MUX_MODE — MUX Mode Select Field. Note: Some functions are available on multiple pins. A given function should not be selected for more than one pin.
    0=ALT0 (Select mux mode: ALT0 mux port: USDHC2_RESET_B of instance: usdhc2); 1=ALT1 (Select mux mode: ALT1 mux port: FLEXSPI_A_SS0_B of instance: flexspi); 2=ALT2 (Select mux mode: ALT2 mux port: LPUART7_CTS_B of instance: lpuart7); 3=ALT3 (Select mux mode: ALT3 mux port: SAI1_RX_DATA00 of instance: sai1); 4=ALT4 (Select mux mode: ALT4 mux port: LPSPI2_PCS0 of instance: lpspi2); 5=ALT5 (Select mux mode: ALT5 mux port: GPIO3_IO06 of instance: gpio3)
0x1F0 SW_MUX_CTL_PAD_GPIO_SD_B1_07 reset 0x5 — SW_MUX_CTL_PAD_GPIO_SD_B1_07 SW MUX Control Register
  [4] SION — Software Input On Field.
    0=DISABLED (Input Path is determined by functionality); 1=ENABLED (Force input path of pad GPIO_SD_B1_07)
  [2:0] MUX_MODE — MUX Mode Select Field. Note: Some functions are available on multiple pins. A given function should not be selected for more than one pin.
    0=ALT0 (Select mux mode: ALT0 mux port: SEMC_CSX1 of instance: semc); 1=ALT1 (Select mux mode: ALT1 mux port: FLEXSPI_A_SCLK of instance: flexspi); 2=ALT2 (Select mux mode: ALT2 mux port: LPUART7_RTS_B of instance: lpuart7); 3=ALT3 (Select mux mode: ALT3 mux port: SAI1_TX_DATA00 of instance: sai1); 4=ALT4 (Select mux mode: ALT4 mux port: LPSPI2_SCK of instance: lpspi2); 5=ALT5 (Select mux mode: ALT5 mux port: GPIO3_IO07 of instance: gpio3); 6=ALT6 (Select mux mode: ALT6 mux port: CCM_REF_EN_B of instance: ccm)
0x1F4 SW_MUX_CTL_PAD_GPIO_SD_B1_08 reset 0x5 — SW_MUX_CTL_PAD_GPIO_SD_B1_08 SW MUX Control Register
  [4] SION — Software Input On Field.
    0=DISABLED (Input Path is determined by functionality); 1=ENABLED (Force input path of pad GPIO_SD_B1_08)
  [2:0] MUX_MODE — MUX Mode Select Field. Note: Some functions are available on multiple pins. A given function should not be selected for more than one pin.
    0=ALT0 (Select mux mode: ALT0 mux port: USDHC2_DATA4 of instance: usdhc2); 1=ALT1 (Select mux mode: ALT1 mux port: FLEXSPI_A_DATA00 of instance: flexspi); 2=ALT2 (Select mux mode: ALT2 mux port: LPUART7_TXD of instance: lpuart7); 3=ALT3 (Select mux mode: ALT3 mux port: SAI1_TX_BCLK of instance: sai1); 4=ALT4 (Select mux mode: ALT4 mux port: LPSPI2_SD0 of instance: lpspi2); 5=ALT5 (Select mux mode: ALT5 mux port: GPIO3_IO08 of instance: gpio3); 6=ALT6 (Select mux mode: ALT6 mux port: SEMC_CSX2 of instance: semc)
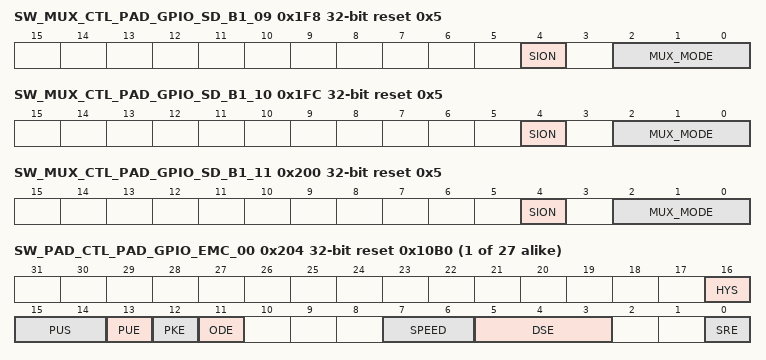
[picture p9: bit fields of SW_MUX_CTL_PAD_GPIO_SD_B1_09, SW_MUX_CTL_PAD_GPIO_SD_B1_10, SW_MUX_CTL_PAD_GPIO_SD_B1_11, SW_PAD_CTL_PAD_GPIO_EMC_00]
0x1F8 SW_MUX_CTL_PAD_GPIO_SD_B1_09 reset 0x5 — SW_MUX_CTL_PAD_GPIO_SD_B1_09 SW MUX Control Register
  [4] SION — Software Input On Field.
    0=DISABLED (Input Path is determined by functionality); 1=ENABLED (Force input path of pad GPIO_SD_B1_09)
  [2:0] MUX_MODE — MUX Mode Select Field. Note: Some functions are available on multiple pins. A given function should not be selected for more than one pin.
    0=ALT0 (Select mux mode: ALT0 mux port: USDHC2_DATA5 of instance: usdhc2); 1=ALT1 (Select mux mode: ALT1 mux port: FLEXSPI_A_DATA1 of instance: flexspi); 2=ALT2 (Select mux mode: ALT2 mux port: LPUART7_RXD of instance: lpuart7); 3=ALT3 (Select mux mode: ALT3 mux port: SAI1_TX_SYNC of instance: sai1); 4=ALT4 (Select mux mode: ALT4 mux port: LPSPI2_SDI of instance: lpspi2); 5=ALT5 (Select mux mode: ALT5 mux port: GPIO3_IO09 of instance: gpio3)
0x1FC SW_MUX_CTL_PAD_GPIO_SD_B1_10 reset 0x5 — SW_MUX_CTL_PAD_GPIO_SD_B1_10 SW MUX Control Register
  [4] SION — Software Input On Field.
    0=DISABLED (Input Path is determined by functionality); 1=ENABLED (Force input path of pad GPIO_SD_B1_10)
  [2:0] MUX_MODE — MUX Mode Select Field. Note: Some functions are available on multiple pins. A given function should not be selected for more than one pin.
    0=ALT0 (Select mux mode: ALT0 mux port: USDHC2_DATA6 of instance: usdhc2); 1=ALT1 (Select mux mode: ALT1 mux port: FLEXSPI_A_DATA2 of instance: flexspi); 2=ALT2 (Select mux mode: ALT2 mux port: LPUART2_RXD of instance: lpuart2); 3=ALT3 (Select mux mode: ALT3 mux port: LPI2C2_SDA of instance: lpi2c2); 4=ALT4 (Select mux mode: ALT4 mux port: LPSPI2_PCS2 of instance: lpspi2); 5=ALT5 (Select mux mode: ALT5 mux port: GPIO3_IO10 of instance: gpio3)
0x200 SW_MUX_CTL_PAD_GPIO_SD_B1_11 reset 0x5 — SW_MUX_CTL_PAD_GPIO_SD_B1_11 SW MUX Control Register
  [4] SION — Software Input On Field.
    0=DISABLED (Input Path is determined by functionality); 1=ENABLED (Force input path of pad GPIO_SD_B1_11)
  [2:0] MUX_MODE — MUX Mode Select Field. Note: Some functions are available on multiple pins. A given function should not be selected for more than one pin.
    0=ALT0 (Select mux mode: ALT0 mux port: USDHC2_DATA7 of instance: usdhc2); 1=ALT1 (Select mux mode: ALT1 mux port: FLEXSPI_A_DATA3 of instance: flexspi); 2=ALT2 (Select mux mode: ALT2 mux port: LPUART2_TXD of instance: lpuart2); 3=ALT3 (Select mux mode: ALT3 mux port: LPI2C2_SCL of instance: lpi2c2); 4=ALT4 (Select mux mode: ALT4 mux port: LPSPI2_PCS3 of instance: lpspi2); 5=ALT5 (Select mux mode: ALT5 mux port: GPIO3_IO11 of instance: gpio3)
{0x204+4i} SW_PAD_CTL_PAD_GPIO_EMC_{i:02} reset 0x10B0 (i=0..26) — SW_PAD_CTL_PAD_GPIO_EMC_{i:02} SW PAD Control Register
  [16] HYS — Hyst. Enable Field
    0=HYS_0_Hysteresis_Disabled (Hysteresis Disabled (CMOS input)); 1=HYS_1_Hysteresis_Enabled (Hysteresis Enabled (Schmitt Trigger input))
  [15:14] PUS — Pull Up / Down Config. Field Controls signals to select pull-up or pull-down internal resistance strength.
    0=PUS_0_100K_Ohm_Pull_Down (100K Ohm Pull Down); 1=PUS_1_47K_Ohm_Pull_Up (47K Ohm Pull Up); 2=PUS_2_100K_Ohm_Pull_Up (100K Ohm Pull Up); 3=PUS_3_22K_Ohm_Pull_Up (22K Ohm Pull Up)
  [13] PUE — Pull / Keep Select Field Control signal to enable internal pull-up/down resistors or pad keeper functionality.
    0=PUE_0_Keeper (Keep the previous output value when the output driver is disabled.); 1=PUE_1_Pull (Pull-up or pull-down (determined by PUS field).)
  [12] PKE — Pull / Keep Enable Field
    0=PKE_0_Pull_Keeper_Disabled (Pull/Keeper Disabled); 1=PKE_1_Pull_Keeper_Enabled (Pull/Keeper Enabled)
  [11] ODE — Open Drain Enable Field
    0=ODE_0_Open_Drain_Disabled (Open Drain Disabled (Output is CMOS)); 1=ODE_1_Open_Drain_Enabled (Open Drain Enabled (Output is Open Drain))
  [7:6] SPEED
    0=SPEED_0_Low (50MHz); 1=SPEED_1_Medium (100MHz - 150MHz); 2=SPEED_2_Medium (100MHz - 150MHz); 3=SPEED_3_Maximum (150MHz - 200MHz)
  [5:3] DSE — Drive Strength Field
    0=HI-Z; 1=Dual/Single voltage: 262/260 Ohm @ 1.8V, 247/157 Ohm @ 3.3V; 2=Dual/Single voltage: 134/130 Ohm @ 1.8V, 126/78 Ohm @ 3.3V; 3=Dual/Single voltage: 88/88 Ohm @ 1.8V, 84/53 Ohm @ 3.3V; 4=Dual/Single voltage: 62/65 Ohm @ 1.8V, 57/39 Ohm @ 3.3V; 5=Dual/Single voltage: 51/52 Ohm @ 1.8V, 47/32 Ohm @ 3.3V; 6=Dual/Single voltage: 43/43 Ohm @ 1.8V, 40/26 Ohm @ 3.3V; 7=Dual/Single voltage: 37/37 Ohm @ 1.8V, 34/23 Ohm @ 3.3V
  [0] SRE — Slew Rate Field
    0=SRE_0_Slow_Slew_Rate (Slow Slew Rate); 1=SRE_1_Fast_Slew_Rate (Fast Slew Rate)
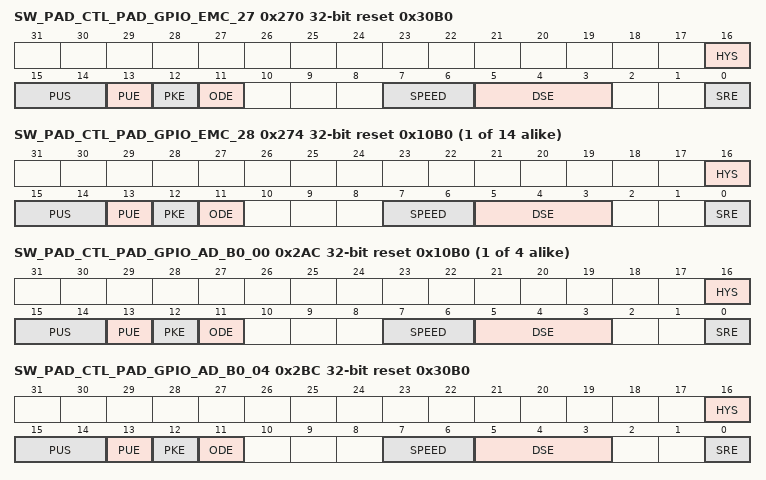
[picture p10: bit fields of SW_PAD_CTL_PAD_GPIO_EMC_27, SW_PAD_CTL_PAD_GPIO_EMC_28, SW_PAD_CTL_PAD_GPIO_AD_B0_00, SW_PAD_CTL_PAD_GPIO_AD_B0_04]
0x270 SW_PAD_CTL_PAD_GPIO_EMC_27 reset 0x30B0 — SW_PAD_CTL_PAD_GPIO_EMC_27 SW PAD Control Register
  fields as SW_PAD_CTL_PAD_GPIO_EMC_00
{0x204+4i} SW_PAD_CTL_PAD_GPIO_EMC_{i} reset 0x10B0 (i=28..41) — SW_PAD_CTL_PAD_GPIO_EMC_{i} SW PAD Control Register
  fields as SW_PAD_CTL_PAD_GPIO_EMC_00
{0x2AC+4i} SW_PAD_CTL_PAD_GPIO_AD_B0_{i:02} reset 0x10B0 (i=0..3) — SW_PAD_CTL_PAD_GPIO_AD_B0_{i:02} SW PAD Control Register
  fields as SW_PAD_CTL_PAD_GPIO_EMC_00
0x2BC SW_PAD_CTL_PAD_GPIO_AD_B0_04 reset 0x30B0 — SW_PAD_CTL_PAD_GPIO_AD_B0_04 SW PAD Control Register
  fields as SW_PAD_CTL_PAD_GPIO_EMC_00
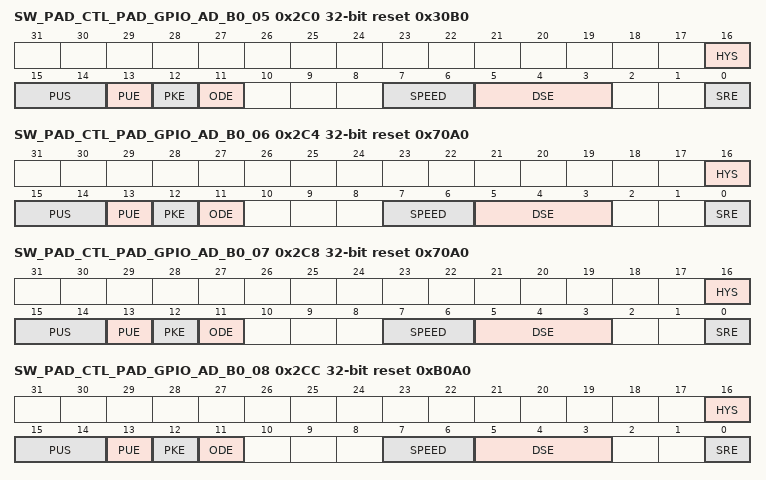
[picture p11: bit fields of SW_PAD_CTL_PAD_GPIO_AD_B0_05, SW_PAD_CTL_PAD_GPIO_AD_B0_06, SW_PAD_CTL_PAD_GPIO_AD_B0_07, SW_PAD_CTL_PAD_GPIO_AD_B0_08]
0x2C0 SW_PAD_CTL_PAD_GPIO_AD_B0_05 reset 0x30B0 — SW_PAD_CTL_PAD_GPIO_AD_B0_05 SW PAD Control Register
  fields as SW_PAD_CTL_PAD_GPIO_EMC_00
0x2C4 SW_PAD_CTL_PAD_GPIO_AD_B0_06 reset 0x70A0 — SW_PAD_CTL_PAD_GPIO_AD_B0_06 SW PAD Control Register
  fields as SW_PAD_CTL_PAD_GPIO_EMC_00
0x2C8 SW_PAD_CTL_PAD_GPIO_AD_B0_07 reset 0x70A0 — SW_PAD_CTL_PAD_GPIO_AD_B0_07 SW PAD Control Register
  fields as SW_PAD_CTL_PAD_GPIO_EMC_00
0x2CC SW_PAD_CTL_PAD_GPIO_AD_B0_08 reset 0xB0A0 — SW_PAD_CTL_PAD_GPIO_AD_B0_08 SW PAD Control Register
  fields as SW_PAD_CTL_PAD_GPIO_EMC_00
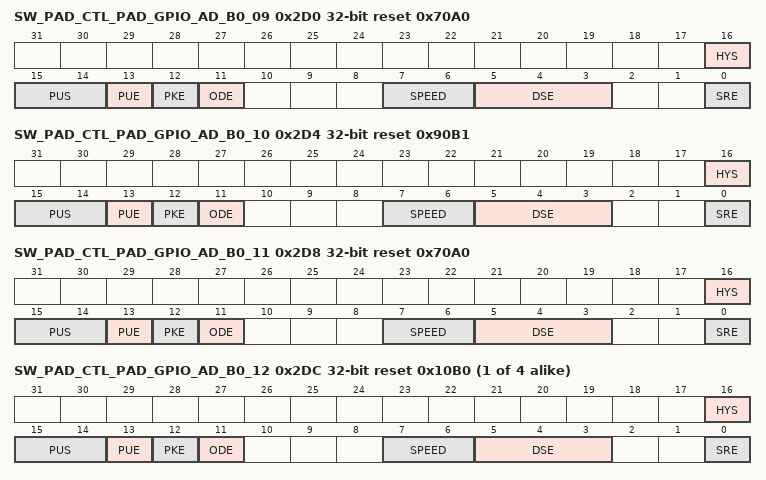
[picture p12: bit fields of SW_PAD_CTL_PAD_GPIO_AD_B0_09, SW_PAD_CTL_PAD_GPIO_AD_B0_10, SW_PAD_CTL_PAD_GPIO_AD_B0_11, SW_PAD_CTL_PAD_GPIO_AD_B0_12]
0x2D0 SW_PAD_CTL_PAD_GPIO_AD_B0_09 reset 0x70A0 — SW_PAD_CTL_PAD_GPIO_AD_B0_09 SW PAD Control Register
  fields as SW_PAD_CTL_PAD_GPIO_EMC_00
0x2D4 SW_PAD_CTL_PAD_GPIO_AD_B0_10 reset 0x90B1 — SW_PAD_CTL_PAD_GPIO_AD_B0_10 SW PAD Control Register
  fields as SW_PAD_CTL_PAD_GPIO_EMC_00
0x2D8 SW_PAD_CTL_PAD_GPIO_AD_B0_11 reset 0x70A0 — SW_PAD_CTL_PAD_GPIO_AD_B0_11 SW PAD Control Register
  fields as SW_PAD_CTL_PAD_GPIO_EMC_00
{0x2AC+4i} SW_PAD_CTL_PAD_GPIO_AD_B0_{i} reset 0x10B0 (i=12..15) — SW_PAD_CTL_PAD_GPIO_AD_B0_{i} SW PAD Control Register
  fields as SW_PAD_CTL_PAD_GPIO_EMC_00
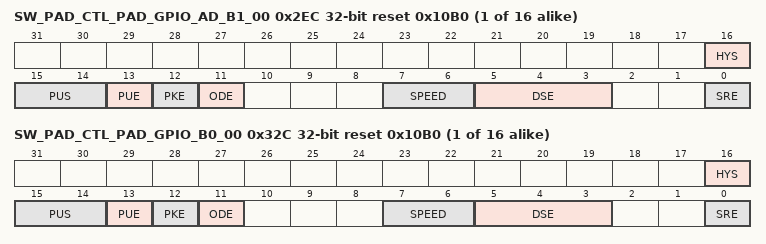
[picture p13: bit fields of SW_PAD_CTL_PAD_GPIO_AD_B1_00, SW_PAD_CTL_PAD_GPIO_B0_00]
{0x2EC+4i} SW_PAD_CTL_PAD_GPIO_AD_B1_{i:02} reset 0x10B0 (i=0..15) — SW_PAD_CTL_PAD_GPIO_AD_B1_{i:02} SW PAD Control Register
  fields as SW_PAD_CTL_PAD_GPIO_EMC_00
{0x32C+4i} SW_PAD_CTL_PAD_GPIO_B0_{i:02} reset 0x10B0 (i=0..15) — SW_PAD_CTL_PAD_GPIO_B0_{i:02} SW PAD Control Register
  fields as SW_PAD_CTL_PAD_GPIO_EMC_00
